# STM32F730x register map
File version: 1.1
CPU: CM7 r0p1, little endian, MPU, FPU, 4 interrupt priority bits
Registers are 32-bit, read-write, reset 0x0 unless marked. A register's access mark holds for its fields unless they carry their own. Offsets are from the block's base; [hi:lo] are bit positions; {n}, {i} and the like mark numbered series.

## SYSCFG — System configuration controller
Base 0x40013800
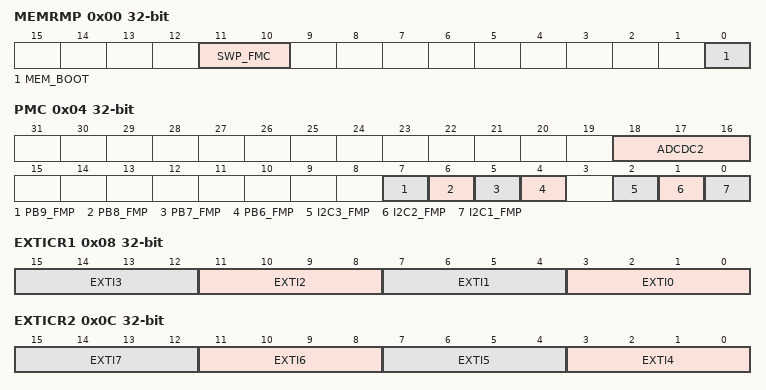
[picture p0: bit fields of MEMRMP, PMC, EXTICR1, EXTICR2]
0x00 MEMRMP — memory remap register
  [11:10] SWP_FMC — FMC memory mapping swap
  [0] MEM_BOOT — Memory boot mapping
0x04 PMC — peripheral mode configuration register
  [18:16] ADCDC2 — ADC3DC2
  [7] PB9_FMP — Fast Mode + Enable
  [6] PB8_FMP — PB8_FMP Fast Mode + Enable
  [5] PB7_FMP — PB7_FMP Fast Mode + Enable
  [4] PB6_FMP — PB6_FMP Fast Mode
  [2] I2C3_FMP — I2C3_FMP I2C3 Fast Mode + Enable
  [1] I2C2_FMP — I2C2_FMP I2C2 Fast Mode + Enable
  [0] I2C1_FMP — I2C1_FMP I2C1 Fast Mode + Enable
0x08 EXTICR1 — external interrupt configuration register 1
  [4n+3:4n] EXTI{n} (n=0..3) — EXTI x configuration (x = 0 to 3)
0x0C EXTICR2 — external interrupt configuration register 2
  [4n-13:4n-16] EXTI{n} (n=4..7) — EXTI x configuration (x = 4 to 7)
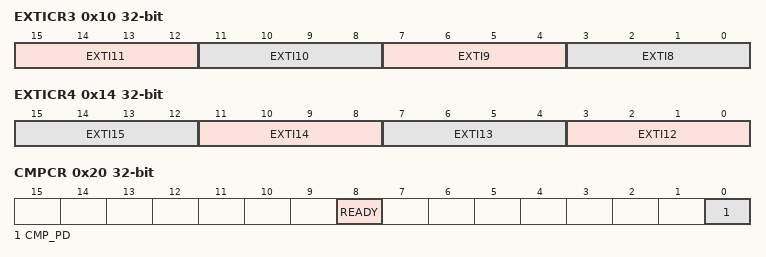
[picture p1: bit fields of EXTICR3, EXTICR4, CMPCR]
0x10 EXTICR3 — external interrupt configuration register 3
  [15:12] EXTI11 — EXTI x configuration (x = 8 to 11)
  [11:8] EXTI10
  [7:4] EXTI9 — EXTI x configuration (x = 8 to 11)
  [3:0] EXTI8 — EXTI x configuration (x = 8 to 11)
0x14 EXTICR4 — external interrupt configuration register 4
  [4n-45:4n-48] EXTI{n} (n=12..15) — EXTI x configuration (x = 12 to 15)
0x20 CMPCR ro — Compensation cell control register
  [8] READY
  [0] CMP_PD — Compensation cell power-down

## OTG_FS_PWRCLK — USB on the go full speed
Base 0x50000E00
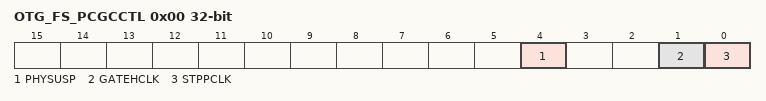
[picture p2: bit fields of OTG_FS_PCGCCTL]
0x00 OTG_FS_PCGCCTL — OTG_FS power and clock gating control register (OTG_FS_PCGCCTL)
  [4] PHYSUSP — PHY Suspended
  [1] GATEHCLK
  [0] STPPCLK — Stop PHY clock

## OTG_HS_PWRCLK — USB on the go high speed
Base 0x40040E00
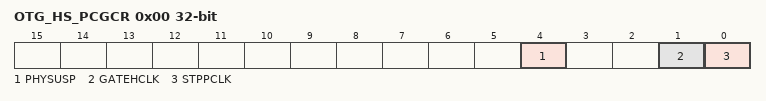
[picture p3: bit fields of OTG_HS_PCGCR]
0x00 OTG_HS_PCGCR — Power and clock gating control register
  [4] PHYSUSP — PHY suspended
  [1] GATEHCLK
  [0] STPPCLK — Stop PHY clock

## WWDG — Window watchdog
Base 0x40002C00
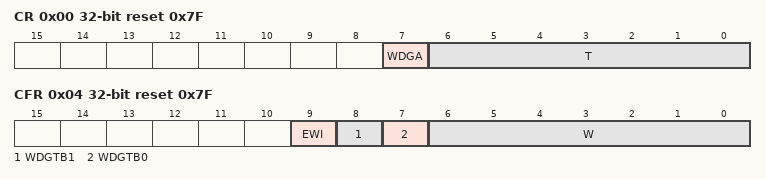
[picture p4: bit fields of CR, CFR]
0x00 CR reset 0x7F — Control register
  [7] WDGA — Activation bit
  [6:0] T — 7-bit counter (MSB to LSB)
0x04 CFR reset 0x7F — Configuration register
  [9] EWI — Early wakeup interrupt
  [8] WDGTB1 — Timer base
  [7] WDGTB0 — Timer base
  [6:0] W — 7-bit window value
0x08 SR — Status register
  [0] EWIF — Early wakeup interrupt flag

## NVIC — Nested Vectored Interrupt Controller
Base 0xE000E100
{0x0+4i} ISER{i} (i=0..2) — Interrupt Set-Enable Register
  [31:0] SETENA
{0x80+4i} ICER{i} (i=0..2) — Interrupt Clear-Enable Register
  [31:0] CLRENA
{0x100+4i} ISPR{i} (i=0..2) — Interrupt Set-Pending Register
  [31:0] SETPEND
{0x180+4i} ICPR{i} (i=0..2) — Interrupt Clear-Pending Register
  [31:0] CLRPEND
{0x200+4i} IABR{i} ro (i=0..2) — Interrupt Active Bit Register
  [31:0] ACTIVE
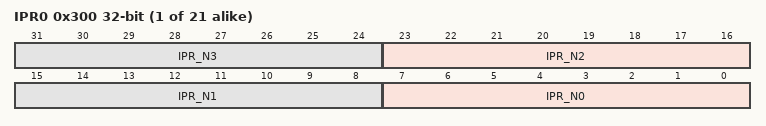
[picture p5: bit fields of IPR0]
{0x300+4i} IPR{i} (i=0..20) — Interrupt Priority Register
  [8n+7:8n] IPR_N{n} (n=0..3)

## MPU — Memory protection unit
Base 0xE000ED90
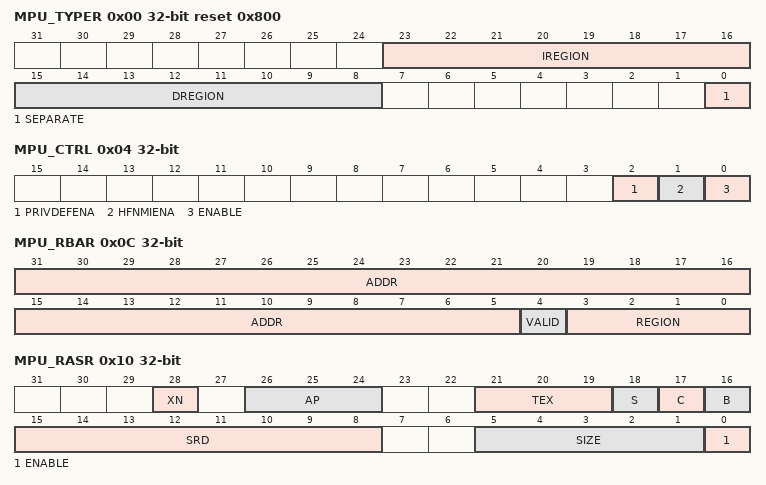
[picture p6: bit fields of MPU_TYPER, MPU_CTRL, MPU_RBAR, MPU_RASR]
0x00 MPU_TYPER ro reset 0x800 — MPU type register
  [23:16] IREGION — Number of MPU instruction regions
  [15:8] DREGION — Number of MPU data regions
  [0] SEPARATE — Separate flag
0x04 MPU_CTRL ro — MPU control register
  [2] PRIVDEFENA — Enable priviliged software access to default memory map
  [1] HFNMIENA — Enables the operation of MPU during hard fault
  [0] ENABLE — Enables the MPU
0x08 MPU_RNR — MPU region number register
  [7:0] REGION — MPU region
0x0C MPU_RBAR — MPU region base address register
  [31:5] ADDR — Region base address field
  [4] VALID — MPU region number valid
  [3:0] REGION — MPU region field
0x10 MPU_RASR — MPU region attribute and size register
  [28] XN — Instruction access disable bit
  [26:24] AP — Access permission
  [21:19] TEX — memory attribute
  [18] S — Shareable memory attribute
  [17] C — memory attribute
  [16] B — memory attribute
  [15:8] SRD — Subregion disable bits
  [5:1] SIZE — Size of the MPU protection region
  [0] ENABLE — Region enable bit.

## STK — SysTick timer
Base 0xE000E010
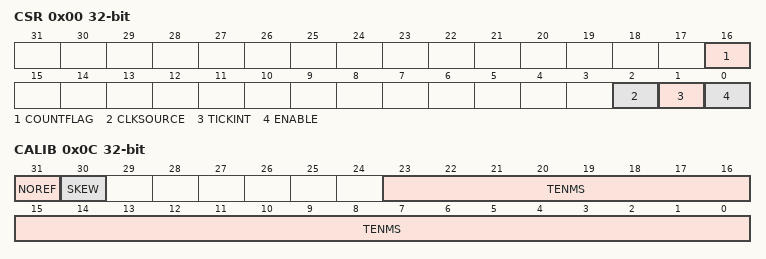
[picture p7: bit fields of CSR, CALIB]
0x00 CSR — SysTick control and status register
  [16] COUNTFLAG
  [2] CLKSOURCE — Clock source selection
  [1] TICKINT — SysTick exception request enable
  [0] ENABLE — Counter enable
0x04 RVR — SysTick reload value register
  [23:0] RELOAD — RELOAD value
0x08 CVR — SysTick current value register
  [23:0] CURRENT — Current counter value
0x0C CALIB — SysTick calibration value register
  [31] NOREF — NOREF flag. Reads as zero
  [30] SKEW — SKEW flag: Indicates whether the TENMS value is exact
  [23:0] TENMS — Calibration value

## NVIC_STIR — Nested vectored interrupt controller
Base 0xE000EF00
0x00 STIR — Software trigger interrupt register
  [8:0] INTID — Software generated interrupt ID

## FPU_CPACR — Floating point unit CPACR
Base 0xE000ED88
0x00 CPACR — Coprocessor access control register
  [23:20] CP

## SCB_ACTRL — System control block ACTLR
Base 0xE000E008
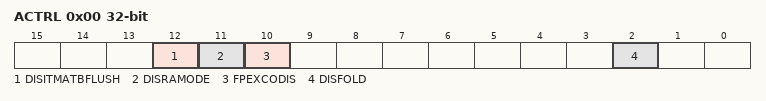
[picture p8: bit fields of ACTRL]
0x00 ACTRL — Auxiliary control register
  [12] DISITMATBFLUSH, [11] DISRAMODE, [10] FPEXCODIS, [2] DISFOLD

## FPU — Floting point unit
Base 0xE000EF34
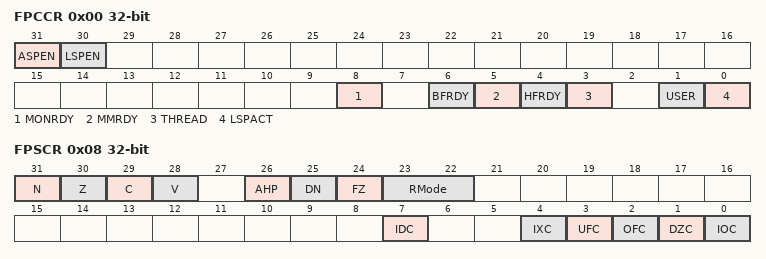
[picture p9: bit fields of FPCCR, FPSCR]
0x00 FPCCR — Floating-point context control register
  [31] ASPEN, [30] LSPEN, [8] MONRDY, [6] BFRDY, [5] MMRDY, [4] HFRDY, [3] THREAD, [1] USER, [0] LSPACT
0x04 FPCAR — Floating-point context address register
  [31:3] ADDRESS — Location of unpopulated floating-point
0x08 FPSCR — Floating-point status control register
  [31] N — Negative condition code flag
  [30] Z — Zero condition code flag
  [29] C — Carry condition code flag
  [28] V — Overflow condition code flag
  [26] AHP — Alternative half-precision control bit
  [25] DN — Default NaN mode control bit
  [24] FZ — Flush-to-zero mode control bit:
  [23:22] RMode — Rounding Mode control field
  [7] IDC — Input denormal cumulative exception bit.
  [4] IXC — Inexact cumulative exception bit
  [3] UFC — Underflow cumulative exception bit
  [2] OFC — Overflow cumulative exception bit
  [1] DZC — Division by zero cumulative exception bit.
  [0] IOC — Invalid operation cumulative exception bit

## PF — Processor features
Base 0xE000ED78
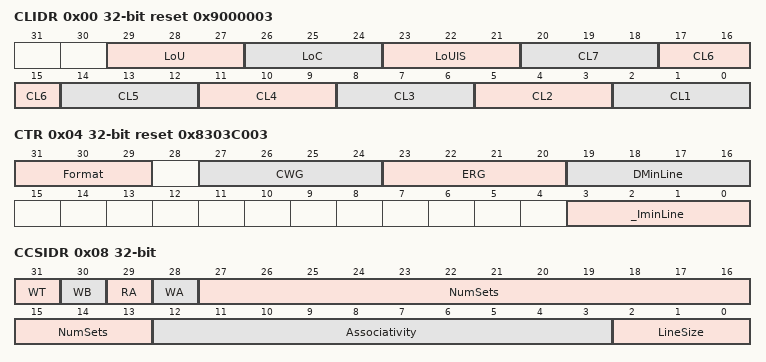
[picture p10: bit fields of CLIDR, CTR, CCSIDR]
0x00 CLIDR ro reset 0x9000003 — Cache Level ID register
  [29:27] LoU, [26:24] LoC, [23:21] LoUIS, [3n-1:3n-3] CL{n} (n=1..7)
0x04 CTR ro reset 0x8303C003 — Cache Type register
  [31:29] Format, [27:24] CWG, [23:20] ERG, [19:16] DMinLine, [3:0] _IminLine
0x08 CCSIDR ro — Cache Size ID register
  [31] WT, [30] WB, [29] RA, [28] WA, [27:13] NumSets, [12:3] Associativity, [2:0] LineSize

## AC — Access control
Base 0xE000EF90
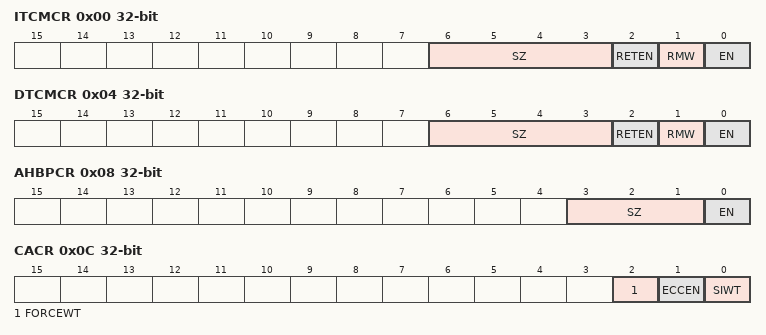
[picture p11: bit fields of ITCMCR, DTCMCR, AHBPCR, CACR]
0x00 ITCMCR — Instruction and Data Tightly-Coupled Memory Control Registers
  [6:3] SZ, [2] RETEN, [1] RMW, [0] EN
0x04 DTCMCR — Instruction and Data Tightly-Coupled Memory Control Registers
  [6:3] SZ, [2] RETEN, [1] RMW, [0] EN
0x08 AHBPCR — AHBP Control register
  [3:1] SZ, [0] EN
0x0C CACR — Auxiliary Cache Control register
  [2] FORCEWT, [1] ECCEN, [0] SIWT
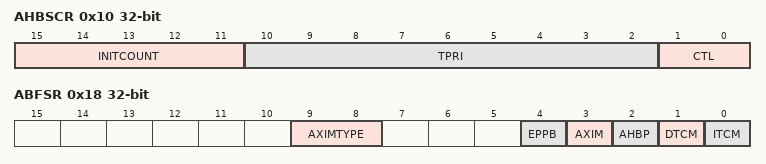
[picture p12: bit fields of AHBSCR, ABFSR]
0x10 AHBSCR — AHB Slave Control register
  [15:11] INITCOUNT, [10:2] TPRI, [1:0] CTL
0x18 ABFSR — Auxiliary Bus Fault Status register
  [9:8] AXIMTYPE, [4] EPPB, [3] AXIM, [2] AHBP, [1] DTCM, [0] ITCM
